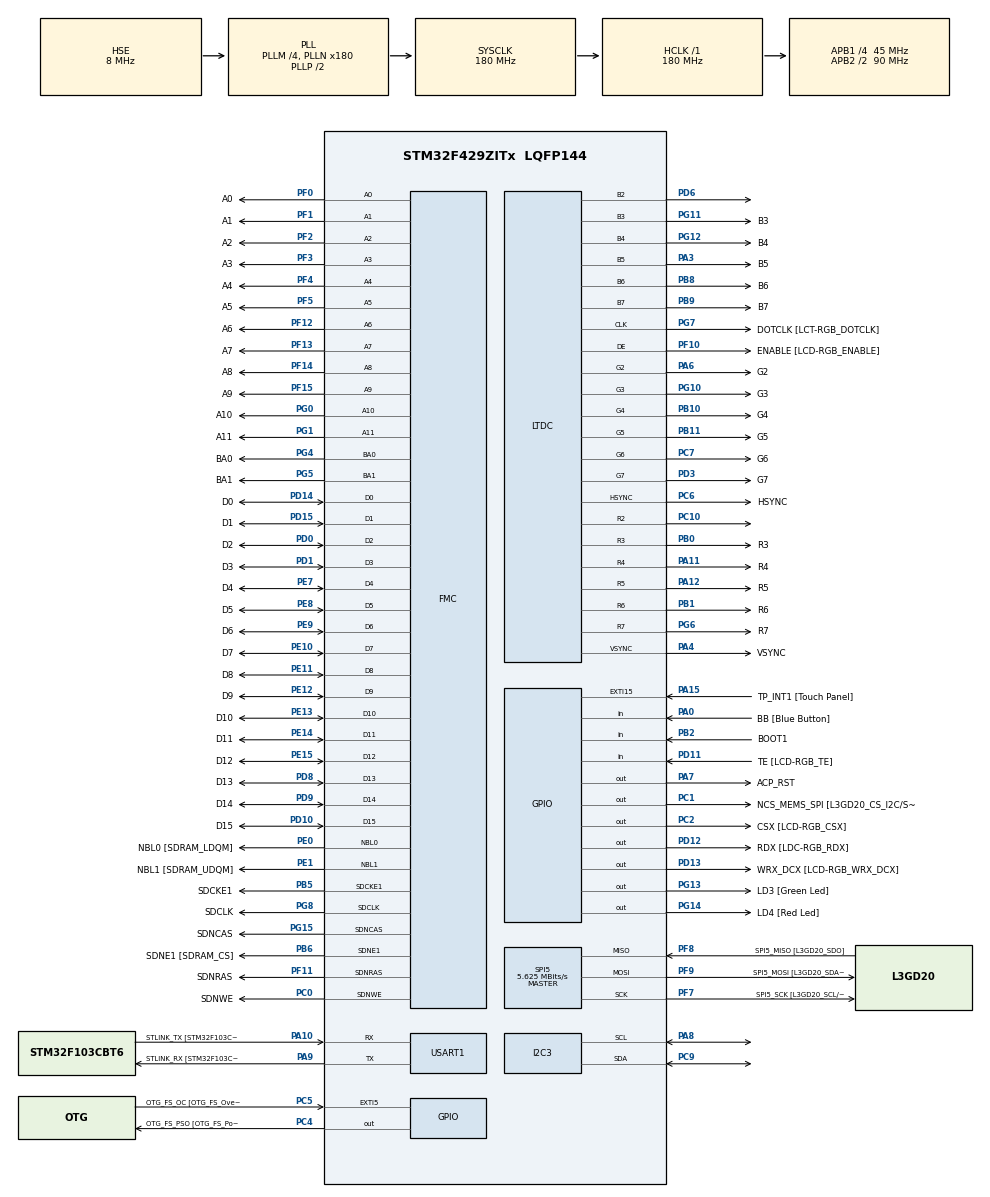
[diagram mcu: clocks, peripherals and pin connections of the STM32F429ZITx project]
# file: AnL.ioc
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DMA2D.ColorMode=DMA2D_OUTPUT_RGB565
FMC.CASLatency1=FMC_SDRAM_CAS_LATENCY_3
FMC.ExitSelfRefreshDelay1=7
FMC.LoadToActiveDelay1=2
FMC.RCDDelay1=2
FMC.RPDelay1=2
FMC.RPDelay2=2
FMC.ReadBurst1=FMC_SDRAM_RBURST_DISABLE
FMC.ReadPipeDelay1=FMC_SDRAM_RPIPE_DELAY_1
FMC.ReadPipeDelay2=FMC_SDRAM_RPIPE_DELAY_1
FMC.RowCycleDelay1=7
FMC.RowCycleDelay2=7
FMC.SDClockPeriod1=FMC_SDRAM_CLOCK_PERIOD_2
FMC.SDClockPeriod2=FMC_SDRAM_CLOCK_PERIOD_2
FMC.SelfRefreshTime1=4
FMC.WriteRecoveryTime1=3
LTDC.ActiveH=320
LTDC.ActiveW=240
LTDC.Alpha_L0=255
LTDC.BlendingFactor1_L0=LTDC_BLENDING_FACTOR1_PAxCA
LTDC.BlendingFactor2_L0=LTDC_BLENDING_FACTOR2_PAxCA
LTDC.FBStartAdress_L0=0xD0000000
LTDC.HBP=20
LTDC.HFP=10
LTDC.HSync=10
LTDC.ImageHeight_L0=320
LTDC.ImageWidth_L0=240
LTDC.Layers=0
LTDC.PixelFormat_L0=LTDC_PIXEL_FORMAT_RGB565
LTDC.VFP=4
LTDC.VSync=2
LTDC.WindowX1_L0=240
LTDC.WindowY1_L0=320
Mcu.Family=STM32F4
Mcu.Name=STM32F429ZITx
Mcu.Package=LQFP144
NVIC.DMA2D_IRQn=true\:5\:0\:true\:false\:true\:true\:true
NVIC.LTDC_IRQn=true\:5\:0\:true\:false\:true\:true\:true
NVIC.PriorityGroup=NVIC_PRIORITYGROUP_4
NVIC.TIM1_TRG_COM_TIM11_IRQn=true\:0\:0\:false\:false\:true\:true\:true
NVIC.TIM1_UP_TIM10_IRQn=true\:0\:0\:false\:false\:true\:true\:true
NVIC.TIM6_DAC_IRQn=true\:0\:0\:false\:false\:true\:false\:true
NVIC.TimeBase=TIM6_DAC_IRQn
NVIC.TimeBaseIP=TIM6
PA0/WKUP.GPIO_Label=BB [Blue Button]
PA0/WKUP.Signal=GPIO_Input
PA10.GPIO_Label=STLINK_TX [STM32F103CBT6_PA2]
PA10.Mode=Asynchronous
PA10.Signal=USART1_RX
PA11.GPIO_Label=R4
PA11.GPIO_Mode=GPIO_MODE_AF_PP
PA11.GPIO_PuPd=GPIO_NOPULL
PA11.GPIO_Speed=GPIO_SPEED_FREQ_LOW
PA11.Mode=RGB666
PA11.Signal=LTDC_R4
PA12.GPIO_Label=R5
PA12.GPIO_Mode=GPIO_MODE_AF_PP
PA12.GPIO_PuPd=GPIO_NOPULL
PA12.GPIO_Speed=GPIO_SPEED_FREQ_LOW
PA12.Mode=RGB666
PA12.Signal=LTDC_R5
PA13.GPIO_Label=SWDIO
PA13.Mode=Serial_Wire
PA13.Signal=SYS_JTMS-SWDIO
PA14.GPIO_Label=SWCLK
PA14.Mode=Serial_Wire
PA14.Signal=SYS_JTCK-SWCLK
PA15.GPIO_Label=TP_INT1 [Touch Panel]
PA15.GPIO_ModeDefaultEXTI=GPIO_MODE_EVT_RISING
PA15.GPIO_PuPd=GPIO_NOPULL
PA15.Signal=GPXTI15
PA3.GPIO_Label=B5
PA3.GPIO_Mode=GPIO_MODE_AF_PP
PA3.GPIO_PuPd=GPIO_NOPULL
PA3.GPIO_Speed=GPIO_SPEED_FREQ_LOW
PA3.Mode=RGB666
PA3.Signal=LTDC_B5
PA4.GPIO_Label=VSYNC
PA4.GPIO_Mode=GPIO_MODE_AF_PP
PA4.GPIO_PuPd=GPIO_NOPULL
PA4.GPIO_Speed=GPIO_SPEED_FREQ_LOW
PA4.Mode=RGB666
PA4.Signal=LTDC_VSYNC
PA6.GPIO_Label=G2
PA6.GPIO_Mode=GPIO_MODE_AF_PP
PA6.GPIO_PuPd=GPIO_NOPULL
PA6.GPIO_Speed=GPIO_SPEED_FREQ_LOW
PA6.Mode=RGB666
PA6.Signal=LTDC_G2
PA7.GPIO_Label=ACP_RST
PA7.GPIO_Mode=GPIO_MODE_OUTPUT_PP
PA7.GPIO_PuPd=GPIO_NOPULL
PA7.GPIO_Speed=GPIO_SPEED_FREQ_LOW
PA7.Signal=GPIO_Output
PA8.Mode=I2C
PA8.Signal=I2C3_SCL
PA9.GPIO_Label=STLINK_RX [STM32F103CBT6_PA3]
PA9.Mode=Asynchronous
PA9.Signal=USART1_TX
PB0.GPIO_Label=R3
PB0.GPIO_Mode=GPIO_MODE_AF_PP
PB0.GPIO_PuPd=GPIO_NOPULL
PB0.GPIO_Speed=GPIO_SPEED_FREQ_LOW
PB0.Mode=RGB666
PB0.Signal=LTDC_R3
PB1.GPIO_Label=R6
PB1.GPIO_Mode=GPIO_MODE_AF_PP
PB1.GPIO_PuPd=GPIO_NOPULL
PB1.GPIO_Speed=GPIO_SPEED_FREQ_LOW
PB1.Mode=RGB666
PB1.Signal=LTDC_R6
PB10.GPIO_Label=G4
PB10.GPIO_Mode=GPIO_MODE_AF_PP
PB10.GPIO_PuPd=GPIO_NOPULL
PB10.GPIO_Speed=GPIO_SPEED_FREQ_LOW
PB10.Mode=RGB666
PB10.Signal=LTDC_G4
PB11.GPIO_Label=G5
PB11.GPIO_Mode=GPIO_MODE_AF_PP
PB11.GPIO_PuPd=GPIO_NOPULL
PB11.GPIO_Speed=GPIO_SPEED_FREQ_LOW
PB11.Mode=RGB666
PB11.Signal=LTDC_G5
PB2/BOOT1.GPIO_Label=BOOT1
PB2/BOOT1.GPIO_Mode=GPIO_MODE_INPUT
PB2/BOOT1.GPIO_PuPd=GPIO_NOPULL
PB2/BOOT1.Signal=GPIO_Input
PB5.GPIO_Label=SDCKE1
PB5.GPIO_Mode=GPIO_MODE_AF_PP
PB5.GPIO_PuPd=GPIO_NOPULL
PB5.GPIO_Speed=GPIO_SPEED_FREQ_VERY_HIGH
PB5.Mode=SdramChipSelect2_1
PB5.Signal=FMC_SDCKE1
PB6.GPIO_Label=SDNE1 [SDRAM_CS]
PB6.GPIO_Mode=GPIO_MODE_AF_PP
PB6.GPIO_PuPd=GPIO_NOPULL
PB6.GPIO_Speed=GPIO_SPEED_FREQ_VERY_HIGH
PB6.Mode=SdramChipSelect2_1
PB6.Signal=FMC_SDNE1
PB8.GPIO_Label=B6
PB8.GPIO_Mode=GPIO_MODE_AF_PP
PB8.GPIO_PuPd=GPIO_NOPULL
PB8.GPIO_Speed=GPIO_SPEED_FREQ_LOW
PB8.Mode=RGB666
PB8.Signal=LTDC_B6
PB9.GPIO_Label=B7
PB9.GPIO_Mode=GPIO_MODE_AF_PP
PB9.GPIO_PuPd=GPIO_NOPULL
PB9.GPIO_Speed=GPIO_SPEED_FREQ_LOW
PB9.Mode=RGB666
PB9.Signal=LTDC_B7
PC0.GPIO_Label=SDNWE
PC0.GPIO_Mode=GPIO_MODE_AF_PP
PC0.GPIO_PuPd=GPIO_NOPULL
PC0.GPIO_Speed=GPIO_SPEED_FREQ_VERY_HIGH
PC0.Signal=FMC_SDNWE
PC1.GPIO_Label=NCS_MEMS_SPI [L3GD20_CS_I2C/SPI]
PC1.GPIO_Mode=GPIO_MODE_OUTPUT_PP
PC1.GPIO_PuPd=GPIO_NOPULL
PC1.GPIO_Speed=GPIO_SPEED_FREQ_LOW
PC1.Signal=GPIO_Output
PC10.Mode=RGB666
PC10.Signal=LTDC_R2
PC2.GPIO_Label=CSX [LCD-RGB_CSX]
PC2.GPIO_Mode=GPIO_MODE_OUTPUT_PP
PC2.GPIO_PuPd=GPIO_NOPULL
PC2.GPIO_Speed=GPIO_SPEED_FREQ_LOW
PC2.Signal=GPIO_Output
PC4.GPIO_Label=OTG_FS_PSO [OTG_FS_PowerSwitchOn]
PC4.GPIO_Mode=GPIO_MODE_OUTPUT_PP
PC4.GPIO_PuPd=GPIO_NOPULL
PC4.GPIO_Speed=GPIO_SPEED_FREQ_LOW
PC4.Signal=GPIO_Output
PC5.GPIO_Label=OTG_FS_OC [OTG_FS_OverCurrent]
PC5.GPIO_ModeDefaultEXTI=GPIO_MODE_EVT_RISING
PC5.Signal=GPXTI5
PC6.GPIO_Label=HSYNC
PC6.GPIO_Mode=GPIO_MODE_AF_PP
PC6.GPIO_PuPd=GPIO_NOPULL
PC6.GPIO_Speed=GPIO_SPEED_FREQ_LOW
PC6.Mode=RGB666
PC6.Signal=LTDC_HSYNC
PC7.GPIO_Label=G6
PC7.GPIO_Mode=GPIO_MODE_AF_PP
PC7.GPIO_PuPd=GPIO_NOPULL
PC7.GPIO_Speed=GPIO_SPEED_FREQ_LOW
PC7.Mode=RGB666
PC7.Signal=LTDC_G6
PC9.Mode=I2C
PC9.Signal=I2C3_SDA
PD0.GPIO_Label=D2
PD0.GPIO_Mode=GPIO_MODE_AF_PP
PD0.GPIO_PuPd=GPIO_NOPULL
PD0.GPIO_Speed=GPIO_SPEED_FREQ_VERY_HIGH
PD0.Signal=FMC_D2_DA2
PD1.GPIO_Label=D3
PD1.GPIO_Mode=GPIO_MODE_AF_PP
PD1.GPIO_PuPd=GPIO_NOPULL
PD1.GPIO_Speed=GPIO_SPEED_FREQ_VERY_HIGH
PD1.Signal=FMC_D3_DA3
PD10.GPIO_Label=D15
PD10.GPIO_Mode=GPIO_MODE_AF_PP
PD10.GPIO_PuPd=GPIO_NOPULL
PD10.GPIO_Speed=GPIO_SPEED_FREQ_VERY_HIGH
PD10.Signal=FMC_D15_DA15
PD11.GPIO_Label=TE [LCD-RGB_TE]
PD11.GPIO_Mode=GPIO_MODE_INPUT
PD11.GPIO_PuPd=GPIO_NOPULL
PD11.Signal=GPIO_Input
PD12.GPIO_Label=RDX [LDC-RGB_RDX]
PD12.GPIO_Mode=GPIO_MODE_OUTPUT_PP
PD12.GPIO_PuPd=GPIO_NOPULL
PD12.GPIO_Speed=GPIO_SPEED_FREQ_LOW
PD12.Signal=GPIO_Output
PD13.GPIO_Label=WRX_DCX [LCD-RGB_WRX_DCX]
PD13.GPIO_Mode=GPIO_MODE_OUTPUT_PP
PD13.GPIO_PuPd=GPIO_NOPULL
PD13.GPIO_Speed=GPIO_SPEED_FREQ_LOW
PD13.Signal=GPIO_Output
PD14.GPIO_Label=D0
PD14.GPIO_Mode=GPIO_MODE_AF_PP
PD14.GPIO_PuPd=GPIO_NOPULL
PD14.GPIO_Speed=GPIO_SPEED_FREQ_VERY_HIGH
PD14.Signal=FMC_D0_DA0
PD15.GPIO_Label=D1
PD15.GPIO_Mode=GPIO_MODE_AF_PP
PD15.GPIO_PuPd=GPIO_NOPULL
PD15.GPIO_Speed=GPIO_SPEED_FREQ_VERY_HIGH
PD15.Signal=FMC_D1_DA1
PD3.GPIO_Label=G7
PD3.GPIO_Mode=GPIO_MODE_AF_PP
PD3.GPIO_PuPd=GPIO_NOPULL
PD3.GPIO_Speed=GPIO_SPEED_FREQ_LOW
PD3.Mode=RGB666
PD3.Signal=LTDC_G7
PD6.Mode=RGB666
PD6.Signal=LTDC_B2
PD8.GPIO_Label=D13
PD8.GPIO_Mode=GPIO_MODE_AF_PP
PD8.GPIO_PuPd=GPIO_NOPULL
PD8.GPIO_Speed=GPIO_SPEED_FREQ_VERY_HIGH
PD8.Signal=FMC_D13_DA13
PD9.GPIO_Label=D14
PD9.GPIO_Mode=GPIO_MODE_AF_PP
PD9.GPIO_PuPd=GPIO_NOPULL
PD9.GPIO_Speed=GPIO_SPEED_FREQ_VERY_HIGH
PD9.Signal=FMC_D14_DA14
PE0.GPIO_Label=NBL0 [SDRAM_LDQM]
PE0.GPIO_Mode=GPIO_MODE_AF_PP
PE0.GPIO_PuPd=GPIO_NOPULL
PE0.GPIO_Speed=GPIO_SPEED_FREQ_VERY_HIGH
PE0.Signal=FMC_NBL0
PE1.GPIO_Label=NBL1 [SDRAM_UDQM]
PE1.GPIO_Mode=GPIO_MODE_AF_PP
PE1.GPIO_PuPd=GPIO_NOPULL
PE1.GPIO_Speed=GPIO_SPEED_FREQ_VERY_HIGH
PE1.Signal=FMC_NBL1
PE10.GPIO_Label=D7
PE10.GPIO_Mode=GPIO_MODE_AF_PP
PE10.GPIO_PuPd=GPIO_NOPULL
PE10.GPIO_Speed=GPIO_SPEED_FREQ_VERY_HIGH
PE10.Signal=FMC_D7_DA7
PE11.GPIO_Label=D8
PE11.GPIO_Mode=GPIO_MODE_AF_PP
PE11.GPIO_PuPd=GPIO_NOPULL
PE11.GPIO_Speed=GPIO_SPEED_FREQ_VERY_HIGH
PE11.Signal=FMC_D8_DA8
PE12.GPIO_Label=D9
PE12.GPIO_Mode=GPIO_MODE_AF_PP
PE12.GPIO_PuPd=GPIO_NOPULL
PE12.GPIO_Speed=GPIO_SPEED_FREQ_VERY_HIGH
PE12.Signal=FMC_D9_DA9
PE13.GPIO_Label=D10
PE13.GPIO_Mode=GPIO_MODE_AF_PP
PE13.GPIO_PuPd=GPIO_NOPULL
PE13.GPIO_Speed=GPIO_SPEED_FREQ_VERY_HIGH
PE13.Signal=FMC_D10_DA10
PE14.GPIO_Label=D11
PE14.GPIO_Mode=GPIO_MODE_AF_PP
PE14.GPIO_PuPd=GPIO_NOPULL
PE14.GPIO_Speed=GPIO_SPEED_FREQ_VERY_HIGH
PE14.Signal=FMC_D11_DA11
PE15.GPIO_Label=D12
PE15.GPIO_Mode=GPIO_MODE_AF_PP
PE15.GPIO_PuPd=GPIO_NOPULL
PE15.GPIO_Speed=GPIO_SPEED_FREQ_VERY_HIGH
PE15.Signal=FMC_D12_DA12
PE7.GPIO_Label=D4
PE7.GPIO_Mode=GPIO_MODE_AF_PP
PE7.GPIO_PuPd=GPIO_NOPULL
PE7.GPIO_Speed=GPIO_SPEED_FREQ_VERY_HIGH
PE7.Signal=FMC_D4_DA4
PE8.GPIO_Label=D5
PE8.GPIO_Mode=GPIO_MODE_AF_PP
PE8.GPIO_PuPd=GPIO_NOPULL
PE8.GPIO_Speed=GPIO_SPEED_FREQ_VERY_HIGH
PE8.Signal=FMC_D5_DA5
PE9.GPIO_Label=D6
PE9.GPIO_Mode=GPIO_MODE_AF_PP
PE9.GPIO_PuPd=GPIO_NOPULL
PE9.GPIO_Speed=GPIO_SPEED_FREQ_VERY_HIGH
PE9.Signal=FMC_D6_DA6
PF0.GPIO_Label=A0
PF0.GPIO_Mode=GPIO_MODE_AF_PP
PF0.GPIO_PuPd=GPIO_NOPULL
PF0.GPIO_Speed=GPIO_SPEED_FREQ_VERY_HIGH
PF0.Signal=FMC_A0
PF1.GPIO_Label=A1
PF1.GPIO_Mode=GPIO_MODE_AF_PP
PF1.GPIO_PuPd=GPIO_NOPULL
PF1.GPIO_Speed=GPIO_SPEED_FREQ_VERY_HIGH
PF1.Signal=FMC_A1
PF10.GPIO_Label=ENABLE [LCD-RGB_ENABLE]
PF10.GPIO_Mode=GPIO_MODE_AF_PP
PF10.GPIO_PuPd=GPIO_NOPULL
PF10.GPIO_Speed=GPIO_SPEED_FREQ_LOW
PF10.Mode=RGB666
PF10.Signal=LTDC_DE
PF11.GPIO_Label=SDNRAS
PF11.GPIO_Mode=GPIO_MODE_AF_PP
PF11.GPIO_PuPd=GPIO_NOPULL
PF11.GPIO_Speed=GPIO_SPEED_FREQ_VERY_HIGH
PF11.Signal=FMC_SDNRAS
PF12.GPIO_Label=A6
PF12.GPIO_Mode=GPIO_MODE_AF_PP
PF12.GPIO_PuPd=GPIO_NOPULL
PF12.GPIO_Speed=GPIO_SPEED_FREQ_VERY_HIGH
PF12.Signal=FMC_A6
PF13.GPIO_Label=A7
PF13.GPIO_Mode=GPIO_MODE_AF_PP
PF13.GPIO_PuPd=GPIO_NOPULL
PF13.GPIO_Speed=GPIO_SPEED_FREQ_VERY_HIGH
PF13.Signal=FMC_A7
PF14.GPIO_Label=A8
PF14.GPIO_Mode=GPIO_MODE_AF_PP
PF14.GPIO_PuPd=GPIO_NOPULL
PF14.GPIO_Speed=GPIO_SPEED_FREQ_VERY_HIGH
PF14.Signal=FMC_A8
PF15.GPIO_Label=A9
PF15.GPIO_Mode=GPIO_MODE_AF_PP
PF15.GPIO_PuPd=GPIO_NOPULL
PF15.GPIO_Speed=GPIO_SPEED_FREQ_VERY_HIGH
PF15.Signal=FMC_A9
PF2.GPIO_Label=A2
PF2.GPIO_Mode=GPIO_MODE_AF_PP
PF2.GPIO_PuPd=GPIO_NOPULL
PF2.GPIO_Speed=GPIO_SPEED_FREQ_VERY_HIGH
PF2.Signal=FMC_A2
PF3.GPIO_Label=A3
PF3.GPIO_Mode=GPIO_MODE_AF_PP
PF3.GPIO_PuPd=GPIO_NOPULL
PF3.GPIO_Speed=GPIO_SPEED_FREQ_VERY_HIGH
PF3.Signal=FMC_A3
PF4.GPIO_Label=A4
PF4.GPIO_Mode=GPIO_MODE_AF_PP
PF4.GPIO_PuPd=GPIO_NOPULL
PF4.GPIO_Speed=GPIO_SPEED_FREQ_VERY_HIGH
PF4.Signal=FMC_A4
PF5.GPIO_Label=A5
PF5.GPIO_Mode=GPIO_MODE_AF_PP
PF5.GPIO_PuPd=GPIO_NOPULL
PF5.GPIO_Speed=GPIO_SPEED_FREQ_VERY_HIGH
PF5.Signal=FMC_A5
PF7.GPIO_Label=SPI5_SCK [L3GD20_SCL/SPC]
PF7.GPIO_Mode=GPIO_MODE_AF_PP
PF7.GPIO_PuPd=GPIO_NOPULL
PF7.GPIO_Speed=GPIO_SPEED_FREQ_LOW
PF7.Mode=Full_Duplex_Master
PF7.Signal=SPI5_SCK
PF8.GPIO_Label=SPI5_MISO [L3GD20_SDO]
PF8.GPIO_Mode=GPIO_MODE_AF_PP
PF8.GPIO_PuPd=GPIO_NOPULL
PF8.GPIO_Speed=GPIO_SPEED_FREQ_LOW
PF8.Mode=Full_Duplex_Master
PF8.Signal=SPI5_MISO
PF9.GPIO_Label=SPI5_MOSI [L3GD20_SDA/SDI/SDO]
PF9.GPIO_Mode=GPIO_MODE_AF_PP
PF9.GPIO_PuPd=GPIO_NOPULL
PF9.GPIO_Speed=GPIO_SPEED_FREQ_LOW
PF9.Mode=Full_Duplex_Master
PF9.Signal=SPI5_MOSI
PG0.GPIO_Label=A10
PG0.GPIO_Mode=GPIO_MODE_AF_PP
PG0.GPIO_PuPd=GPIO_NOPULL
PG0.GPIO_Speed=GPIO_SPEED_FREQ_VERY_HIGH
PG0.Signal=FMC_A10
PG1.GPIO_Label=A11
PG1.GPIO_Mode=GPIO_MODE_AF_PP
PG1.GPIO_PuPd=GPIO_NOPULL
PG1.GPIO_Speed=GPIO_SPEED_FREQ_VERY_HIGH
PG1.Signal=FMC_A11
PG10.GPIO_Label=G3
PG10.GPIO_Mode=GPIO_MODE_AF_PP
PG10.GPIO_PuPd=GPIO_NOPULL
PG10.GPIO_Speed=GPIO_SPEED_FREQ_LOW
PG10.Mode=RGB666
PG10.Signal=LTDC_G3
PG11.GPIO_Label=B3
PG11.GPIO_Mode=GPIO_MODE_AF_PP
PG11.GPIO_PuPd=GPIO_NOPULL
PG11.GPIO_Speed=GPIO_SPEED_FREQ_LOW
PG11.Mode=RGB666
PG11.Signal=LTDC_B3
PG12.GPIO_Label=B4
PG12.GPIO_Mode=GPIO_MODE_AF_PP
PG12.GPIO_PuPd=GPIO_NOPULL
PG12.GPIO_Speed=GPIO_SPEED_FREQ_LOW
PG12.Mode=RGB666
PG12.Signal=LTDC_B4
PG13.GPIO_Label=LD3 [Green Led]
PG13.GPIO_Mode=GPIO_MODE_OUTPUT_PP
PG13.GPIO_PuPd=GPIO_NOPULL
PG13.GPIO_Speed=GPIO_SPEED_FREQ_LOW
PG13.Signal=GPIO_Output
PG14.GPIO_Label=LD4 [Red Led]
PG14.GPIO_Mode=GPIO_MODE_OUTPUT_PP
PG14.GPIO_PuPd=GPIO_NOPULL
PG14.GPIO_Speed=GPIO_SPEED_FREQ_LOW
PG14.Signal=GPIO_Output
PG15.GPIO_Label=SDNCAS
PG15.GPIO_Mode=GPIO_MODE_AF_PP
PG15.GPIO_PuPd=GPIO_NOPULL
PG15.GPIO_Speed=GPIO_SPEED_FREQ_VERY_HIGH
PG15.Signal=FMC_SDNCAS
PG4.GPIO_Label=BA0
PG4.GPIO_Mode=GPIO_MODE_AF_PP
PG4.GPIO_PuPd=GPIO_NOPULL
PG4.GPIO_Speed=GPIO_SPEED_FREQ_VERY_HIGH
PG4.Signal=FMC_A14_BA0
PG5.GPIO_Label=BA1
PG5.GPIO_Mode=GPIO_MODE_AF_PP
PG5.GPIO_PuPd=GPIO_NOPULL
PG5.GPIO_Speed=GPIO_SPEED_FREQ_VERY_HIGH
PG5.Signal=FMC_A15_BA1
PG6.GPIO_Label=R7
PG6.GPIO_Mode=GPIO_MODE_AF_PP
PG6.GPIO_PuPd=GPIO_NOPULL
PG6.GPIO_Speed=GPIO_SPEED_FREQ_LOW
PG6.Mode=RGB666
PG6.Signal=LTDC_R7
PG7.GPIO_Label=DOTCLK [LCT-RGB_DOTCLK]
PG7.GPIO_Mode=GPIO_MODE_AF_PP
PG7.GPIO_PuPd=GPIO_NOPULL
PG7.GPIO_Speed=GPIO_SPEED_FREQ_LOW
PG7.Mode=RGB666
PG7.Signal=LTDC_CLK
PG8.GPIO_Label=SDCLK
PG8.GPIO_Mode=GPIO_MODE_AF_PP
PG8.GPIO_PuPd=GPIO_NOPULL
PG8.GPIO_Speed=GPIO_SPEED_FREQ_VERY_HIGH
PG8.Signal=FMC_SDCLK
PH0/OSC_IN.GPIO_Label=PH0-OSC_IN
PH0/OSC_IN.Mode=HSE-External-Oscillator
PH0/OSC_IN.Signal=RCC_OSC_IN
PH1/OSC_OUT.GPIO_Label=PH1-OSC_OUT
PH1/OSC_OUT.Mode=HSE-External-Oscillator
PH1/OSC_OUT.Signal=RCC_OSC_OUT
ProjectManager.HeapSize=0x200
ProjectManager.StackSize=0x400
ProjectManager.TargetToolchain=TrueSTUDIO
RCC.48MHZClocksFreq_Value=120000000
RCC.AHBFreq_Value=180000000
RCC.APB1CLKDivider=RCC_HCLK_DIV4
RCC.APB1Freq_Value=45000000
RCC.APB1TimFreq_Value=90000000
RCC.APB2CLKDivider=RCC_HCLK_DIV2
RCC.APB2Freq_Value=90000000
RCC.APB2TimFreq_Value=180000000
RCC.CortexFreq_Value=180000000
RCC.HCLKFreq_Value=180000000
RCC.HSE_VALUE=8000000
RCC.HSI_VALUE=16000000
RCC.LSE_VALUE=32768
RCC.PLLM=4
RCC.PLLN=180
RCC.PLLQ=3
RCC.PLLSAIN=192
RCC.PLLSourceVirtual=RCC_PLLSOURCE_HSE
RCC.SYSCLKFreq_VALUE=180000000
RCC.SYSCLKSource=RCC_SYSCLKSOURCE_PLLCLK
RCC.VCOOutputFreq_Value=360000000
SH.FMC_A0.0=FMC_A0,12b-sda1
SH.FMC_A1.0=FMC_A1,12b-sda1
SH.FMC_A10.0=FMC_A10,12b-sda1
SH.FMC_A11.0=FMC_A11,12b-sda1
SH.FMC_A14_BA0.0=FMC_BA0,FourSdramBanks1
SH.FMC_A15_BA1.0=FMC_BA1,FourSdramBanks1
SH.FMC_A2.0=FMC_A2,12b-sda1
SH.FMC_A3.0=FMC_A3,12b-sda1
SH.FMC_A4.0=FMC_A4,12b-sda1
SH.FMC_A5.0=FMC_A5,12b-sda1
SH.FMC_A6.0=FMC_A6,12b-sda1
SH.FMC_A7.0=FMC_A7,12b-sda1
SH.FMC_A8.0=FMC_A8,12b-sda1
SH.FMC_A9.0=FMC_A9,12b-sda1
SH.FMC_D0_DA0.0=FMC_D0,sd-16b-d1
SH.FMC_D10_DA10.0=FMC_D10,sd-16b-d1
SH.FMC_D11_DA11.0=FMC_D11,sd-16b-d1
SH.FMC_D12_DA12.0=FMC_D12,sd-16b-d1
SH.FMC_D13_DA13.0=FMC_D13,sd-16b-d1
SH.FMC_D14_DA14.0=FMC_D14,sd-16b-d1
SH.FMC_D15_DA15.0=FMC_D15,sd-16b-d1
SH.FMC_D1_DA1.0=FMC_D1,sd-16b-d1
SH.FMC_D2_DA2.0=FMC_D2,sd-16b-d1
SH.FMC_D3_DA3.0=FMC_D3,sd-16b-d1
SH.FMC_D4_DA4.0=FMC_D4,sd-16b-d1
SH.FMC_D5_DA5.0=FMC_D5,sd-16b-d1
SH.FMC_D6_DA6.0=FMC_D6,sd-16b-d1
SH.FMC_D7_DA7.0=FMC_D7,sd-16b-d1
SH.FMC_D8_DA8.0=FMC_D8,sd-16b-d1
SH.FMC_D9_DA9.0=FMC_D9,sd-16b-d1
SH.FMC_NBL0.0=FMC_NBL0,Sd2ByteEnable1
SH.FMC_NBL1.0=FMC_NBL1,Sd2ByteEnable1
SH.FMC_SDCLK.0=FMC_SDCLK,12b-sda1
SH.FMC_SDNCAS.0=FMC_SDNCAS,12b-sda1
SH.FMC_SDNRAS.0=FMC_SDNRAS,12b-sda1
SH.FMC_SDNWE.0=FMC_SDNWE,12b-sda1
SPI5.BaudRatePrescaler=SPI_BAUDRATEPRESCALER_16
SPI5.CalculateBaudRate=5.625 MBits/s
SPI5.Direction=SPI_DIRECTION_2LINES
SPI5.Mode=SPI_MODE_MASTER
SPI5.VirtualType=VM_MASTER
TIM10.Period=288
TIM10.Prescaler=9999
TIM11.Period=71
TIM11.Prescaler=9999
USART1.VirtualMode=VM_ASYNC
VP_CRC_VS_CRC.Mode=CRC_Activate
VP_DMA2D_VS_DMA2D.Mode=DMA2D_Activate
VP_SYS_VS_tim6.Mode=TIM6
VP_TIM10_VS_ClockSourceINT.Mode=Enable_Timer
VP_TIM11_VS_ClockSourceINT.Mode=Enable_Timer
VP_TIM1_VS_ClockSourceINT.Mode=Internal
board=32F429IDISCOVERY

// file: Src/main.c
/* USER CODE BEGIN Header */
/**
 ******************************************************************************
 * @file           : main.c
 * @brief          : Main program body
 ******************************************************************************
 * @attention
 *
 * <h2><center>&copy; Copyright (c) 2019 STMicroelectronics.
 * All rights reserved.</center></h2>
 *
 * This software component is licensed by ST under Ultimate Liberty license
 * SLA0044, the "License"; You may not use this file except in compliance with
 * the License. You may obtain a copy of the License at:
 *                             www.st.com/SLA0044
 *
 ******************************************************************************
 */
/* USER CODE END Header */

#include "main.h"
#include "crc.h"
#include "dma2d.h"
#include "gfxsimulator.h"
#include "i2c.h"
#include "ltdc.h"
#include "spi.h"
#include "tim.h"
#include "usart.h"
#include "gpio.h"
#include "fmc.h"

/* USER CODE BEGIN Includes */
#include "../Drivers/BSP/STM32F429I-Discovery/stm32f429i_discovery_lcd.h"
#include "../Drivers/BSP/STM32F429I-Discovery/stm32f429i_discovery_gyroscope.h"
#include "../Drivers/BSP/STM32F429I-Discovery/Fonts/fonts.h"
//#include "Menu.h"
#include "Menu_kontynuuj.h"
#include "Menu_nowagra.h"
#include "Menu_poziomy.h"
//#include "mapa1.h"
#include "mapa2.h"
//#include "SciezkaMapy1.h"
#include "PunktySciezki.h"

/* USER CODE END Includes */

/* USER CODE BEGIN PD */
#define SPOWOLNIENIE_KULKI 5

/* USER CODE END PD */

/* USER CODE BEGIN PV */
volatile ZyroskopDane DataOld, DataNow;
volatile int32_t AngleX, AngleY, AngleZ;

//Dane dla czesci testowej*****************
volatile ZyroskopDane DataTempRom[4];
volatile ZyroskopDane DataTempRich;

volatile int32_t CalkaTrapX, CalkaTrapY;
volatile int32_t CalkaRichaX, CalkaRichaY;
volatile int32_t CalkaRombX, CalkaRombY;
volatile int32_t CalkaPosrednia1X, CalkaPosrednia1Y;
volatile int32_t CalkaPosrednia2X, CalkaPosrednia2Y;
volatile int32_t CalkaPosredniaRomX[4];
volatile int32_t CalkaPosredniaRomY[4];
volatile int32_t CalkaPomocniczaRomX[3];
volatile int32_t CalkaPomocniczaRomY[3];
volatile int32_t CalkaPomocnicza2RomX[2];
volatile int32_t CalkaPomocnicza2RomY[2];

volatile uint8_t LicznikPomocniczy;
volatile uint8_t LicznikPomocniczyRomberg;

volatile int32_t X_pri;
volatile int32_t X_post;
volatile int32_t V_priX;
volatile int32_t V_postX;

volatile int32_t Y_pri;
volatile int32_t Y_post;
volatile int32_t V_priY;
volatile int32_t V_postY;
//*****************************************

//Zmienne stanu gry************************
volatile eStanGry StanGry;
volatile eStanMenu StanMenu;
volatile uint8_t ZmienionoStanMenu;
volatile uint8_t ZmienionoStanPoziomow;
volatile uint8_t WybranyPoziom;
volatile uint32_t czasZmiany;
volatile uint8_t RozpoczetoNowaGre;
volatile uint8_t CzyGra;
volatile uint8_t KontynuowanaGra;
volatile uint8_t Wygrana;
//*****************************************

//Zmiana stanu przycisku*******************
GPIO_PinState StanPrzycisku;
GPIO_PinState PoprzedniStanPrzycisku = GPIO_PIN_RESET;
uint32_t PoprzedniCzasPrzycisku;
//*****************************************

//Zmiana rozgrywki*************************
volatile uint32_t PozycjaNaSciezce;
volatile uint8_t OpoznienieDodatniX;
volatile uint8_t OpoznienieDodatniY;
volatile uint8_t OpoznienieUjemnyX;
volatile uint8_t OpoznienieUjemnyY;
//*****************************************

float dT;
uint8_t Animacja;
volatile uint16_t X, Y;
volatile uint16_t PoprzednieX, PoprzednieY;
volatile uint8_t Direction;
volatile uint8_t fMovedX;
volatile uint8_t fMovedY;
volatile uint16_t ResetTimeX;
volatile uint16_t ResetTimeY;

DMA2D_HandleTypeDef hdma2d;
I2C_HandleTypeDef hi2c3;
LTDC_HandleTypeDef hltdc;
SPI_HandleTypeDef hspi5;
SDRAM_HandleTypeDef hsdram1;
/* USER CODE END PV */

void SystemClock_Config(void);

/* USER CODE BEGIN 0 */
uint8_t spi5_sendrecv(uint8_t byte) {
	uint8_t answer;

	HAL_SPI_TransmitReceive(&hspi5, &byte, &answer, 1, HAL_MAX_DELAY);

	return answer;
}

uint8_t SPI5_read(uint8_t address) {
	uint8_t dane;
	HAL_GPIO_WritePin(GPIOC, GPIO_PIN_1, GPIO_PIN_RESET);
	spi5_sendrecv(address | 0x80);
	dane = spi5_sendrecv(0xFF);
	HAL_GPIO_WritePin(GPIOC, GPIO_PIN_1, GPIO_PIN_SET);

	return dane;
}

void SPI5_write(uint8_t address, uint8_t data) {
	HAL_GPIO_WritePin(GPIOC, GPIO_PIN_1, GPIO_PIN_RESET);
	spi5_sendrecv(address);
	data = spi5_sendrecv(data);
	HAL_GPIO_WritePin(GPIOC, GPIO_PIN_1, GPIO_PIN_SET);

}

uint8_t OurL3GD20_Init() {
	if (SPI5_read(0x0F) != 0b11010100) {

		return 1;
	}

	//Enable L3GD20 Power bit
	SPI5_write(0x20, 0xFF);

	//Set L3GD20 scale

	SPI5_write(0x23, 0x00);

	//Set high-pass filter settings
	SPI5_write(0x21, 0x00);

	//Enable high-pass filter
	SPI5_write(0x24, 0x10);

	//Everything OK
	return 0;
}

void OurL3GD20_Read() {
	float s;
	short temp1, temp2, temp3;

	// Read X axis

	temp1 = (SPI5_read(0x28) | SPI5_read(0x29) << 8);
	temp2 = (SPI5_read(0x2A) | SPI5_read(0x2B) << 8);
	temp3 = (SPI5_read(0x2C) | SPI5_read(0x2D) << 8);

	// Sensitivity at 250 range = 8.75 mdps/digit
	s = 8.75 * 0.001;

	DataNow.OsX = (short) ((float) temp1 * s);
	DataNow.OsY = (short) ((float) temp2 * s);
	DataNow.OsZ = (short) ((float) temp3 * s);

}

void send_char(char c) {
	HAL_UART_Transmit(&huart1, (uint8_t*) &c, 1, 1000);
}

int __io_putchar(int ch) {
	send_char(ch);
	return ch;
}

/* USER CODE END 0 */

int main(void) {

	/* MCU Configuration--------------------------------------------------------*/

	/* Reset of all peripherals, Initializes the Flash interface and the Systick. */
	HAL_Init();

	/* Configure the system clock */
	SystemClock_Config();

	/* Initialize all configured peripherals */
	MX_GPIO_Init();
	MX_CRC_Init();
	MX_DMA2D_Init();
	MX_FMC_Init();
	MX_LTDC_Init();
	MX_SPI5_Init();
	MX_TIM1_Init();
	MX_USART1_UART_Init();
	MX_I2C3_Init();
	MX_TIM10_Init();
	MX_TIM11_Init();
	MX_GFXSIMULATOR_Init();
	/* USER CODE BEGIN 2 */

	__HAL_SPI_ENABLE(&hspi5);

	//Do testu*************
	LicznikPomocniczy = 0;
	LicznikPomocniczyRomberg = 0;
	//*********************

	//Poczatkowy stan gry**
	StanGry = Menu;
	StanMenu = NowaGra;
	ZmienionoStanMenu = 1;
	ZmienionoStanPoziomow = 1;
	WybranyPoziom = 0;
	RozpoczetoNowaGre = 0;
	CzyGra = 0;
	KontynuowanaGra = 0;
	Wygrana = 0;
	//*********************

	OpoznienieDodatniX = 0;
	OpoznienieDodatniY = 0;
	OpoznienieUjemnyX = 0;
	OpoznienieUjemnyY = 0;

	Animacja = 0;
	Direction = 1;
	X = 120;
	Y = 170;
	dT = 0.001;
	fMovedX = 0;
	fMovedY = 0;
	ResetTimeX = 0;
	ResetTimeY = 0;

	BSP_LCD_Init();
	//BSP_LCD_LayerDefaultInit(LCD_FOREGROUND_LAYER, LCD_FRAME_BUFFER+1024*1024*4);
	BSP_LCD_LayerDefaultInit(LCD_BACKGROUND_LAYER, LCD_FRAME_BUFFER);

	BSP_LCD_SelectLayer(LCD_BACKGROUND_LAYER);

	BSP_LCD_DisplayOn();
	BSP_LCD_Clear(LCD_COLOR_BLACK);

	//Zakomentowac po uruchomieniu menu
	//BSP_LCD_DrawBitmap(0, 0, (uint8_t*) image_data_Menu);
//  HAL_Delay(2000);
//  BSP_LCD_DrawBitmap(0, 0, (uint8_t*) image_data_Menu_nowagra);
//  HAL_Delay(2000);
//  BSP_LCD_DrawBitmap(0, 0, (uint8_t*) image_data_Menu_kontynuuj);
//  HAL_Delay(2000);
//  BSP_LCD_DrawBitmap(0, 0, (uint8_t*) image_data_Menu_poziomy);
//  //*********************************

	//BSP_LCD_SetTextColor(LCD_COLOR_DARKGRAY);
	//BSP_LCD_DisplayStringAtLine(5, (uint8_t*) "Hello");

	HAL_Delay(1000);
	BSP_LCD_ClearStringLine(5);

	BSP_LCD_Clear(LCD_COLOR_WHITE);

//  //Zakomentowac po uruchomieniu menu
//  BSP_LCD_SetTextColor(LCD_COLOR_BLACK);
//  BSP_LCD_FillRect(0, 0, 240, 15);
//  BSP_LCD_FillRect(0, 305, 240, 15);
//  BSP_LCD_FillRect(0, 15, 15, 290);
//  BSP_LCD_FillRect(225, 15, 15, 290);
	//*********************************

	if (BSP_GYRO_Init() == GYRO_ERROR) {
		printf("Nie udalo sie polaczyc z zyroskopem");
		HAL_Delay(10000);
	}

	czasZmiany = 0;
	HAL_TIM_Base_Start_IT(&htim10);
	HAL_TIM_Base_Start_IT(&htim11);

	//Zakomentuj przy sprawdzaniu menu !!!!!!!!!!!!!!!!!
//  Animacja = 1;
	//!!!!!!!!!!!!!!!!!!!!!!!!!!!!!!!!!!!!!!!!!!!!!!!!!!

	GPIO_PinState OdczytanyStanPrzycisku;

	/* USER CODE END 2 */

	/* Infinite loop */
	/* USER CODE BEGIN WHILE */
	while (1) {

		if (HAL_GetTick() - czasZmiany > 1500) {
			if (StanGry == Menu) {

				StanMenu = (StanMenu + 1) % 3;
				ZmienionoStanMenu = 1;

			} else if (StanGry == WyborPoziomu) {
				WybranyPoziom = (WybranyPoziom + 1) % 3;
				ZmienionoStanPoziomow = 1;
			}

			czasZmiany = HAL_GetTick();
		}
		//Sprawdzanie stanu przycisku*****************
		OdczytanyStanPrzycisku = HAL_GPIO_ReadPin(BB_GPIO_Port, BB_Pin);

		if (OdczytanyStanPrzycisku != PoprzedniStanPrzycisku) {
			PoprzedniCzasPrzycisku = HAL_GetTick();
		}

		if ((HAL_GetTick() - PoprzedniCzasPrzycisku) > 10) {
			if (OdczytanyStanPrzycisku != StanPrzycisku) {
				StanPrzycisku = OdczytanyStanPrzycisku;

				//  if (StanPrzycisku == GPIO_PIN_RESET) { //StanGry = Gra;
//                  if (StanGry == Menu) {
//                      StanMenu = (StanMenu + 1) % 3;
//                      ZmienionoStanMenu = 1;
//
//                  } else if (StanGry == WyborPoziomu) {
//                      WybranyPoziom = (WybranyPoziom + 1) % 3;
//                      ZmienionoStanPoziomow = 1;
//                  }
				//}

				//Przetestowac !!!!!!!!!!!!!!!!!
				//Jezeli przytrzymamy przycisk dluzej nastapi przejscie miedzy gra, a menu
				if (StanPrzycisku == GPIO_PIN_SET) {

					if (StanGry == Menu && StanMenu == NowaGra) {
						StanGry = Gra;
						RozpoczetoNowaGre = 1;
						CzyGra = 1;

					} else if (StanGry == Menu && StanMenu == KontynuujGre
							&& CzyGra == 1) {
						StanGry = Gra;
						KontynuowanaGra = 1;
					} else if (StanGry == Menu && StanMenu == ZmienPoziom) {
						StanGry = WyborPoziomu;
						WybranyPoziom = 0;
						ZmienionoStanPoziomow = 1;

					} else if (StanGry == WyborPoziomu) {
						StanGry = Menu;

					} else if (StanGry == Gra) {
						StanGry = Menu;
					}

					PoprzedniCzasPrzycisku = HAL_GetTick();

				}
			}
		}

		PoprzedniStanPrzycisku = OdczytanyStanPrzycisku;

		//Koniec sprawdzania stanu przycisku**********

		//Petla gry***********************************

		if (StanGry == Menu)

		{
			X_pri = 0;
			V_priX = 0;

			X_post = 0;
			V_postX = 0;

			Y_pri = 0;
			V_priY = 0;

			Y_post = 0;
			V_postY = 0;
			HAL_TIM_Base_Stop_IT(&htim11);
			if (ZmienionoStanMenu == 1) {
				switch (StanMenu) {
				case NowaGra:
					BSP_LCD_DrawBitmap(0, 0,
							(uint8_t*) image_data_Menu_nowagra);
					break;

				case KontynuujGre:
					BSP_LCD_DrawBitmap(0, 0,
							(uint8_t*) image_data_Menu_kontynuuj);
					break;

				case ZmienPoziom:

					BSP_LCD_DrawBitmap(0, 0,
							(uint8_t*) image_data_Menu_poziomy);
					break;
				}

				ZmienionoStanMenu = 0;
			}

		} else if (StanGry == WyborPoziomu) {
			if (ZmienionoStanPoziomow == 1) {
				switch (WybranyPoziom) {
				case 0:
					BSP_LCD_Clear(LCD_COLOR_WHITE);
					BSP_LCD_SetTextColor(LCD_COLOR_GREEN);
					BSP_LCD_FillRect(20, 20, 60, 60);
					BSP_LCD_DisplayChar(30, 30, 49);
					BSP_LCD_SetTextColor(LCD_COLOR_BLACK);

					BSP_LCD_FillRect(90, 20, 60, 60);
					BSP_LCD_DisplayChar(100, 30, 50);

					BSP_LCD_FillRect(160, 20, 60, 60);
					BSP_LCD_DisplayChar(170, 30, 51);
					break;

				case 1:
					BSP_LCD_Clear(LCD_COLOR_WHITE);
					BSP_LCD_SetTextColor(LCD_COLOR_BLACK);
					BSP_LCD_FillRect(20, 20, 60, 60);
					BSP_LCD_DisplayChar(30, 30, 49);

					BSP_LCD_SetTextColor(LCD_COLOR_GREEN);
					BSP_LCD_FillRect(90, 20, 60, 60);
					BSP_LCD_DisplayChar(100, 30, 50);

					BSP_LCD_SetTextColor(LCD_COLOR_BLACK);
					BSP_LCD_FillRect(160, 20, 60, 60);
					BSP_LCD_DisplayChar(170, 30, 51);
					break;

				case 2:
					BSP_LCD_Clear(LCD_COLOR_WHITE);
					BSP_LCD_SetTextColor(LCD_COLOR_BLACK);
					BSP_LCD_FillRect(20, 20, 60, 60);
					BSP_LCD_DisplayChar(30, 30, 49);

					BSP_LCD_SetTextColor(LCD_COLOR_BLACK);
					BSP_LCD_FillRect(90, 20, 60, 60);
					BSP_LCD_DisplayChar(100, 30, 50);

					BSP_LCD_SetTextColor(LCD_COLOR_GREEN);
					BSP_LCD_FillRect(160, 20, 60, 60);
					BSP_LCD_DisplayChar(170, 30, 51);
					break;

				default:
					break;
				}

				ZmienionoStanPoziomow = 0;
			}

		} else if (StanGry == Gra) {
			HAL_TIM_Base_Start_IT(&htim11);

			if (Wygrana == 1) {
				HAL_TIM_Base_Stop_IT(&htim11);
				BSP_LCD_Clear(LCD_COLOR_WHITE);
				BSP_LCD_SetTextColor(LCD_COLOR_RED);
				BSP_LCD_DisplayStringAt(10, 30, (uint8_t*) "WYGRANA",
						CENTER_MODE);

				BSP_LCD_SetTextColor(LCD_COLOR_WHITE);

				HAL_Delay(2000);

				WybranyPoziom = (WybranyPoziom + 1) % 3;
				RozpoczetoNowaGre = 1;
				Wygrana = 0;
				X_pri = 0;
				V_priX = 0;

				X_post = 0;
				V_postX = 0;

				Y_pri = 0;
				V_priY = 0;

				Y_post = 0;
				V_postY = 0;
				HAL_TIM_Base_Start_IT(&htim11);
			}

			if (WybranyPoziom == 0 && RozpoczetoNowaGre == 1) {
				BSP_LCD_Clear(LCD_COLOR_BLACK);
				BSP_LCD_SetTextColor(LCD_COLOR_WHITE);

				for (uint32_t i = 1; i <= IloscPunktowSciezki1; i++) {
					if (PunktySciezki1[i].SasiedniePunkty[0] != 0) {
						for (int j = -6; j < 7; j++) {
							BSP_LCD_DrawLine(PunktySciezki1[i].X - 6,
									PunktySciezki1[i].Y + j,
									PunktySciezki1[PunktySciezki1[i].SasiedniePunkty[0]].X
											+ 6,
									PunktySciezki1[PunktySciezki1[i].SasiedniePunkty[0]].Y
											+ j);
						}

					}

					if (PunktySciezki1[i].SasiedniePunkty[2] != 0) {
						for (int j = -6; j < 7; j++) {
							BSP_LCD_DrawLine(PunktySciezki1[i].X + j,
									PunktySciezki1[i].Y - 6,
									PunktySciezki1[PunktySciezki1[i].SasiedniePunkty[2]].X
											+ j,
									PunktySciezki1[PunktySciezki1[i].SasiedniePunkty[2]].Y
											+ 6);
						}
					}
				}

				PozycjaNaSciezce = 1;

				BSP_LCD_SetTextColor(LCD_COLOR_RED);

				BSP_LCD_FillCircle(PunktySciezki1[PozycjaNaSciezce].X,
						PunktySciezki1[PozycjaNaSciezce].Y, 5);

				X = PunktySciezki1[PozycjaNaSciezce].X;
				Y = PunktySciezki1[PozycjaNaSciezce].Y;

				PoprzednieX = X;
				PoprzednieY = Y;

				BSP_LCD_SetTextColor(LCD_COLOR_CYAN);
				BSP_LCD_FillRect(PunktySciezki1[IloscPunktowSciezki1].X - 6,
						PunktySciezki1[IloscPunktowSciezki1].Y - 6, 13, 13);

				BSP_LCD_SetTextColor(LCD_COLOR_WHITE);

				RozpoczetoNowaGre = 0;

			} else if (WybranyPoziom == 1 && RozpoczetoNowaGre == 1) {
				BSP_LCD_Clear(LCD_COLOR_BLACK);
				BSP_LCD_SetTextColor(LCD_COLOR_WHITE);

				for (uint32_t i = 1; i <= IloscPunktowSciezki2; i++) {
					if (PunktySciezki2[i].SasiedniePunkty[0] != 0) {
						for (int j = -6; j < 7; j++) {
							BSP_LCD_DrawLine(PunktySciezki2[i].X - 6,
									PunktySciezki2[i].Y + j,
									PunktySciezki2[PunktySciezki2[i].SasiedniePunkty[0]].X
											+ 6,
									PunktySciezki2[PunktySciezki2[i].SasiedniePunkty[0]].Y
											+ j);
						}

					}

					if (PunktySciezki2[i].SasiedniePunkty[2] != 0) {
						for (int j = -6; j < 7; j++) {
							BSP_LCD_DrawLine(PunktySciezki2[i].X + j,
									PunktySciezki2[i].Y - 6,
									PunktySciezki2[PunktySciezki2[i].SasiedniePunkty[2]].X
											+ j,
									PunktySciezki2[PunktySciezki2[i].SasiedniePunkty[2]].Y
											+ 6);
						}
					}
				}

				PozycjaNaSciezce = 1;

				BSP_LCD_SetTextColor(LCD_COLOR_RED);

				BSP_LCD_FillCircle(PunktySciezki2[PozycjaNaSciezce].X,
						PunktySciezki2[PozycjaNaSciezce].Y, 5);

				X = PunktySciezki2[PozycjaNaSciezce].X;
				Y = PunktySciezki2[PozycjaNaSciezce].Y;

				PoprzednieX = X;
				PoprzednieY = Y;

				BSP_LCD_SetTextColor(LCD_COLOR_CYAN);
				BSP_LCD_FillRect(PunktySciezki2[IloscPunktowSciezki2].X - 6,
						PunktySciezki2[IloscPunktowSciezki2].Y - 6, 13, 13);

				BSP_LCD_SetTextColor(LCD_COLOR_WHITE);

				RozpoczetoNowaGre = 0;

			} else if (WybranyPoziom == 2 && RozpoczetoNowaGre == 1) {
				BSP_LCD_Clear(LCD_COLOR_BLACK);
				BSP_LCD_SetTextColor(LCD_COLOR_WHITE);

				for (uint32_t i = 1; i <= IloscPunktowSciezki3; i++) {
					if (PunktySciezki3[i].SasiedniePunkty[0] != 0) {
						for (int j = -6; j < 7; j++) {
							BSP_LCD_DrawLine(PunktySciezki3[i].X - 6,
									PunktySciezki3[i].Y + j,
									PunktySciezki3[PunktySciezki3[i].SasiedniePunkty[0]].X
											+ 6,
									PunktySciezki3[PunktySciezki3[i].SasiedniePunkty[0]].Y
											+ j);
						}

					}

					if (PunktySciezki3[i].SasiedniePunkty[2] != 0) {
						for (int j = -6; j < 7; j++) {
							BSP_LCD_DrawLine(PunktySciezki3[i].X + j,
									PunktySciezki3[i].Y - 6,
									PunktySciezki3[PunktySciezki3[i].SasiedniePunkty[2]].X
											+ j,
									PunktySciezki3[PunktySciezki3[i].SasiedniePunkty[2]].Y
											+ 6);
						}
					}
				}

				PozycjaNaSciezce = 1;

				BSP_LCD_SetTextColor(LCD_COLOR_RED);

				BSP_LCD_FillCircle(PunktySciezki3[PozycjaNaSciezce].X,
						PunktySciezki3[PozycjaNaSciezce].Y, 5);

				X = PunktySciezki3[PozycjaNaSciezce].X;
				Y = PunktySciezki3[PozycjaNaSciezce].Y;

				PoprzednieX = X;
				PoprzednieY = Y;

				BSP_LCD_SetTextColor(LCD_COLOR_CYAN);
				BSP_LCD_FillRect(PunktySciezki3[IloscPunktowSciezki3].X - 6,
						PunktySciezki3[IloscPunktowSciezki3].Y - 6, 13, 13);

				BSP_LCD_SetTextColor(LCD_COLOR_WHITE);

				RozpoczetoNowaGre = 0;

			} else if (WybranyPoziom == 0 && KontynuowanaGra == 1) {
				BSP_LCD_Clear(LCD_COLOR_BLACK);
				BSP_LCD_SetTextColor(LCD_COLOR_WHITE);

				for (uint32_t i = 1; i <= IloscPunktowSciezki1; i++) {
					if (PunktySciezki1[i].SasiedniePunkty[0] != 0) {
						for (int j = -6; j < 7; j++) {
							BSP_LCD_DrawLine(PunktySciezki1[i].X - 6,
									PunktySciezki1[i].Y + j,
									PunktySciezki1[PunktySciezki1[i].SasiedniePunkty[0]].X
											+ 6,
									PunktySciezki1[PunktySciezki1[i].SasiedniePunkty[0]].Y
											+ j);
						}

					}

					if (PunktySciezki1[i].SasiedniePunkty[2] != 0) {
						for (int j = -6; j < 7; j++) {
							BSP_LCD_DrawLine(PunktySciezki1[i].X + j,
									PunktySciezki1[i].Y - 6,
									PunktySciezki1[PunktySciezki1[i].SasiedniePunkty[2]].X
											+ j,
									PunktySciezki1[PunktySciezki1[i].SasiedniePunkty[2]].Y
											+ 6);
						}
					}
				}

				BSP_LCD_SetTextColor(LCD_COLOR_RED);

				//BSP_LCD_FillCircle(PunktySciezki1[PozycjaNaSciezce].X, PunktySciezki1[PozycjaNaSciezce].Y, 5);

				BSP_LCD_SetTextColor(LCD_COLOR_CYAN);
				BSP_LCD_FillRect(PunktySciezki1[IloscPunktowSciezki1].X - 6,
						PunktySciezki1[IloscPunktowSciezki1].Y - 6, 13, 13);

				BSP_LCD_SetTextColor(LCD_COLOR_WHITE);

				KontynuowanaGra = 0;

			} else if (WybranyPoziom == 1 && KontynuowanaGra == 1) {
				BSP_LCD_Clear(LCD_COLOR_BLACK);
				BSP_LCD_SetTextColor(LCD_COLOR_WHITE);

				for (uint32_t i = 1; i <= IloscPunktowSciezki2; i++) {
					if (PunktySciezki2[i].SasiedniePunkty[0] != 0) {
						for (int j = -6; j < 7; j++) {
							BSP_LCD_DrawLine(PunktySciezki2[i].X - 6,
									PunktySciezki2[i].Y + j,
									PunktySciezki2[PunktySciezki2[i].SasiedniePunkty[0]].X
											+ 6,
									PunktySciezki2[PunktySciezki2[i].SasiedniePunkty[0]].Y
											+ j);
						}

					}

					if (PunktySciezki2[i].SasiedniePunkty[2] != 0) {
						for (int j = -6; j < 7; j++) {
							BSP_LCD_DrawLine(PunktySciezki2[i].X + j,
									PunktySciezki2[i].Y - 6,
									PunktySciezki2[PunktySciezki2[i].SasiedniePunkty[2]].X
											+ j,
									PunktySciezki2[PunktySciezki2[i].SasiedniePunkty[2]].Y
											+ 6);
						}
					}
				}

				BSP_LCD_SetTextColor(LCD_COLOR_RED);

				//BSP_LCD_FillCircle(PunktySciezki2[PozycjaNaSciezce].X, PunktySciezki2[PozycjaNaSciezce].Y, 5);

				BSP_LCD_SetTextColor(LCD_COLOR_CYAN);
				BSP_LCD_FillRect(PunktySciezki2[IloscPunktowSciezki2].X - 6,
						PunktySciezki2[IloscPunktowSciezki2].Y - 6, 13, 13);

				BSP_LCD_SetTextColor(LCD_COLOR_WHITE);

				KontynuowanaGra = 0;

			} else if (WybranyPoziom == 2 && KontynuowanaGra == 1) {
				BSP_LCD_Clear(LCD_COLOR_BLACK);
				BSP_LCD_SetTextColor(LCD_COLOR_WHITE);

				for (uint32_t i = 1; i <= IloscPunktowSciezki3; i++) {
					if (PunktySciezki3[i].SasiedniePunkty[0] != 0) {
						for (int j = -6; j < 7; j++) {
							BSP_LCD_DrawLine(PunktySciezki3[i].X - 6,
									PunktySciezki3[i].Y + j,
									PunktySciezki3[PunktySciezki3[i].SasiedniePunkty[0]].X
											+ 6,
									PunktySciezki3[PunktySciezki3[i].SasiedniePunkty[0]].Y
											+ j);
						}

					}

					if (PunktySciezki3[i].SasiedniePunkty[2] != 0) {
						for (int j = -6; j < 7; j++) {
							BSP_LCD_DrawLine(PunktySciezki3[i].X + j,
									PunktySciezki3[i].Y - 6,
									PunktySciezki3[PunktySciezki3[i].SasiedniePunkty[2]].X
											+ j,
									PunktySciezki3[PunktySciezki3[i].SasiedniePunkty[2]].Y
											+ 6);
						}
					}
				}

				BSP_LCD_SetTextColor(LCD_COLOR_RED);

				//BSP_LCD_FillCircle(PunktySciezki3[PozycjaNaSciezce].X, PunktySciezki3[PozycjaNaSciezce].Y, 5);

				BSP_LCD_SetTextColor(LCD_COLOR_CYAN);
				BSP_LCD_FillRect(PunktySciezki3[IloscPunktowSciezki3].X - 6,
						PunktySciezki3[IloscPunktowSciezki3].Y - 6, 13, 13);

				BSP_LCD_SetTextColor(LCD_COLOR_WHITE);

				KontynuowanaGra = 0;
			}

		}

		//Koniec petli gry****************************
//
//        printf("Angle X: %li\n\r", AngleX);
//        printf("Angle Y: %li\n\r", AngleY);
//        printf("Angle Z: %li\n\r", AngleZ);
//        printf("CzasX: %d\n\r", ResetTimeX);
//        printf("CzasY: %d\n\r", ResetTimeY);
//        printf("Predkosc X: %d\n\r", DataNow.OsX);
//        printf("Predkosc Y: %d\n\r", DataNow.OsY);

		//Do testu************************************
		/*printf("CalkaTrap X: %li\n\r", CalkaTrapX);
		 printf("CalkaTrap Y: %li\n\r", CalkaTrapY);

		 printf("CalkaRicha X: %li\n\r", CalkaRichaX);
		 printf("CalkaRicha Y: %li\n\r", CalkaRichaY);*/

		//printf("CalkaRomb X: %li\n\r", CalkaRombX);
		//printf("CalkaRomb Y: %li\n\r", CalkaRombY);
		//********************************************
		//printf("OsX: %d\n\r", Data.OsX);
		//printf("OsY: %d\n\r", Data.OsY);
		//printf("OsZ: %d\n\r", Data.OsZ);
		//HAL_Delay(200);
		/* USER CODE END WHILE */

	}
}

void SystemClock_Config(void) {
	RCC_OscInitTypeDef RCC_OscInitStruct = { 0 };
	RCC_ClkInitTypeDef RCC_ClkInitStruct = { 0 };
	RCC_PeriphCLKInitTypeDef PeriphClkInitStruct = { 0 };

	/** Configure the main internal regulator output voltage
	 */
	__HAL_RCC_PWR_CLK_ENABLE()
	;
	__HAL_PWR_VOLTAGESCALING_CONFIG(PWR_REGULATOR_VOLTAGE_SCALE1);
	/** Initializes the CPU, AHB and APB busses clocks
	 */
	RCC_OscInitStruct.OscillatorType = RCC_OSCILLATORTYPE_HSE;
	RCC_OscInitStruct.HSEState = RCC_HSE_ON;
	RCC_OscInitStruct.PLL.PLLState = RCC_PLL_ON;
	RCC_OscInitStruct.PLL.PLLSource = RCC_PLLSOURCE_HSE;
	RCC_OscInitStruct.PLL.PLLM = 4;
	RCC_OscInitStruct.PLL.PLLN = 180;
	RCC_OscInitStruct.PLL.PLLP = RCC_PLLP_DIV2;
	RCC_OscInitStruct.PLL.PLLQ = 3;
	if (HAL_RCC_OscConfig(&RCC_OscInitStruct) != HAL_OK) {
		Error_Handler();
	}
	/** Activate the Over-Drive mode
	 */
	if (HAL_PWREx_EnableOverDrive() != HAL_OK) {
		Error_Handler();
	}
	/** Initializes the CPU, AHB and APB busses clocks
	 */
	RCC_ClkInitStruct.ClockType = RCC_CLOCKTYPE_HCLK | RCC_CLOCKTYPE_SYSCLK
			| RCC_CLOCKTYPE_PCLK1 | RCC_CLOCKTYPE_PCLK2;
	RCC_ClkInitStruct.SYSCLKSource = RCC_SYSCLKSOURCE_PLLCLK;
	RCC_ClkInitStruct.AHBCLKDivider = RCC_SYSCLK_DIV1;
	RCC_ClkInitStruct.APB1CLKDivider = RCC_HCLK_DIV4;
	RCC_ClkInitStruct.APB2CLKDivider = RCC_HCLK_DIV2;

	if (HAL_RCC_ClockConfig(&RCC_ClkInitStruct, FLASH_LATENCY_5) != HAL_OK) {
		Error_Handler();
	}
	PeriphClkInitStruct.PeriphClockSelection = RCC_PERIPHCLK_LTDC;
	PeriphClkInitStruct.PLLSAI.PLLSAIN = 192;
	PeriphClkInitStruct.PLLSAI.PLLSAIR = 2;
	PeriphClkInitStruct.PLLSAIDivR = RCC_PLLSAIDIVR_2;
	if (HAL_RCCEx_PeriphCLKConfig(&PeriphClkInitStruct) != HAL_OK) {
		Error_Handler();
	}
}

void HAL_TIM_PeriodElapsedCallback(TIM_HandleTypeDef *htim) {
	/* USER CODE BEGIN Callback 0 */
	if (htim->Instance == TIM10) //Przerwanie pochodzi od timera 10
	{
		;
	}

	if (htim->Instance == TIM11) {
		OurL3GD20_Read();
		if (DataNow.OsX < 10 && DataNow.OsX > -10) {
			DataNow.OsX = 0;
			V_postX = 0;

		}

		if (DataNow.OsY < 10 && DataNow.OsY > -10) {
			DataNow.OsY = 0;
			V_postY = 0;
		}

		if (DataNow.OsZ < 10 && DataNow.OsZ > -10)
			DataNow.OsZ = 0;

		X_pri = X_post + (int32_t) (0.4 * V_postX);
		V_priX = V_postX;

		X_post = X_pri + (int32_t) (0.9 * (DataNow.OsX - V_priX) * 0.4);
		V_postX = V_priX + (int32_t) (0.05 * (DataNow.OsX - V_priX));

		Y_pri = Y_post + (int32_t) (0.4 * V_postY);
		V_priY = V_postY;

		Y_post = Y_pri + (int32_t) (0.9 * (DataNow.OsY - V_priY) * 0.4);
		V_postY = V_priY + (int32_t) (0.05 * (DataNow.OsY - V_priY));

		//To mozna wsumie przy testowaniu wywalic za czesc testowa
		if ((DataNow.OsX >= 25 && DataNow.OsY <= 20)
				|| (DataNow.OsX <= -25 && DataNow.OsY >= -20))
			AngleX +=
					(long) (DataNow.OsX + ((DataOld.OsX - DataNow.OsX) * 0.5));
		else if ((DataNow.OsX >= 25 && DataNow.OsY >= 25)
				|| (DataNow.OsX <= -25 && DataNow.OsY <= -25))
			AngleX +=
					(long) (DataNow.OsX + ((DataOld.OsX - DataNow.OsX) * 0.5));

		if ((DataNow.OsY >= 25 && DataNow.OsX <= 20)
				|| (DataNow.OsY <= -25 && DataNow.OsX >= -20))
			AngleY +=
					(long) (DataNow.OsY + ((DataOld.OsY - DataNow.OsY) * 0.5));
		else if ((DataNow.OsX >= 25 && DataNow.OsY >= 25)
				|| (DataNow.OsX <= -25 && DataNow.OsY <= -25))
			AngleY +=
					(long) (DataNow.OsY + ((DataOld.OsY - DataNow.OsY) * 0.5));

//*************TESTOWA CZESC*****************************************************************************************

		/*//Liczenie calki metoda wietu trapezow
		 CalkaTrapX += (long) (4 * ((DataOld.OsX + DataNow.OsX) * 0.5)); //Czas miedzy kolejnymi pomiarami rowny 0.004 s, pomnozony przez 1000 zeby nie miec liczby z przecinkiem
		 CalkaTrapY += (long) (4 * ((DataOld.OsY + DataNow.OsY) * 0.5));
		 //koniec

		 //Liczenie calki za pomoca ekstrapolacji Richardsona
		 if (LicznikPomocniczy == 0) {
		 CalkaPosrednia2X = (long) (4 * ((DataOld.OsX + DataNow.OsX) * 0.5));
		 CalkaPosrednia2Y = (long) (4 * ((DataOld.OsY + DataNow.OsY) * 0.5));

		 DataTempRich = DataOld;

		 LicznikPomocniczy = 1;

		 } else {
		 CalkaPosrednia2X +=
		 (long) (4 * ((DataOld.OsX + DataNow.OsX) * 0.5));
		 CalkaPosrednia2Y +=
		 (long) (4 * ((DataOld.OsY + DataNow.OsY) * 0.5));

		 CalkaPosrednia1X = (long) (8
		 * ((DataTempRich.OsX + DataNow.OsX) * 0.5));
		 CalkaPosrednia1Y = (long) (8
		 * ((DataTempRich.OsY + DataNow.OsY) * 0.5));

		 CalkaRichaX += (long) (CalkaPosrednia2X)
		 + ((CalkaPosrednia2X - CalkaPosrednia1X) / 3);
		 CalkaRichaY += (long) (CalkaPosrednia2Y)
		 + ((CalkaPosrednia2Y - CalkaPosrednia1Y) / 3);
		 LicznikPomocniczy = 0;
		 }
		 */
		//koniec
		//Liczenie calki za pomoca metody Romberga
		if (LicznikPomocniczyRomberg == 0) {
			DataTempRom[0] = DataOld;

			CalkaPosredniaRomX[3] = (long) (4
					* ((DataOld.OsX + DataNow.OsX) * 0.5));
			CalkaPosredniaRomY[3] = (long) (4
					* ((DataOld.OsY + DataNow.OsY) * 0.5));

			LicznikPomocniczyRomberg = 1;

		} else if (LicznikPomocniczyRomberg == 1) {
			CalkaPosredniaRomX[3] += (long) (4
					* ((DataOld.OsX + DataNow.OsX) * 0.5));
			CalkaPosredniaRomY[3] += (long) (4
					* ((DataOld.OsY + DataNow.OsY) * 0.5));

			CalkaPosredniaRomX[2] = (long) (8
					* ((DataTempRom[0].OsX + DataNow.OsX) * 0.5));
			CalkaPosredniaRomY[2] = (long) (8
					* ((DataTempRom[0].OsY + DataNow.OsY) * 0.5));

			LicznikPomocniczyRomberg = 2;

		} else if (LicznikPomocniczyRomberg == 2) {
			DataTempRom[2] = DataOld;

			CalkaPosredniaRomX[3] += (long) (4
					* ((DataOld.OsX + DataNow.OsX) * 0.5));
			CalkaPosredniaRomY[3] += (long) (4
					* ((DataOld.OsY + DataNow.OsY) * 0.5));

			LicznikPomocniczyRomberg = 3;

		} else if (LicznikPomocniczyRomberg == 3) {
			CalkaPosredniaRomX[3] += (long) (4
					* ((DataOld.OsX + DataNow.OsX) * 0.5));
			CalkaPosredniaRomY[3] += (long) (4
					* ((DataOld.OsY + DataNow.OsY) * 0.5));

			CalkaPosredniaRomX[2] += (long) (8
					* ((DataTempRom[2].OsX + DataNow.OsX) * 0.5));
			CalkaPosredniaRomY[2] += (long) (8
					* ((DataTempRom[2].OsY + DataNow.OsY) * 0.5));

			CalkaPosredniaRomX[1] = (long) (16
					* ((DataTempRom[0].OsX + DataNow.OsX) * 0.5));
			CalkaPosredniaRomY[1] = (long) (16
					* ((DataTempRom[0].OsY + DataNow.OsY) * 0.5));

			LicznikPomocniczyRomberg = 4;

		} else if (LicznikPomocniczyRomberg == 4) {
			DataTempRom[1] = DataOld;

			CalkaPosredniaRomX[3] += (long) (4
					* ((DataOld.OsX + DataNow.OsX) * 0.5));
			CalkaPosredniaRomY[3] += (long) (4
					* ((DataOld.OsY + DataNow.OsY) * 0.5));

			LicznikPomocniczyRomberg = 5;

		} else if (LicznikPomocniczyRomberg == 5) {
			CalkaPosredniaRomX[3] += (long) (4
					* ((DataOld.OsX + DataNow.OsX) * 0.5));
			CalkaPosredniaRomY[3] += (long) (4
					* ((DataOld.OsY + DataNow.OsY) * 0.5));

			CalkaPosredniaRomX[2] += (long) (8
					* ((DataTempRom[1].OsX + DataNow.OsX) * 0.5));
			CalkaPosredniaRomY[2] += (long) (8
					* ((DataTempRom[1].OsY + DataNow.OsY) * 0.5));

			LicznikPomocniczyRomberg = 6;

		} else if (LicznikPomocniczyRomberg == 6) {
			DataTempRom[3] = DataOld;

			CalkaPosredniaRomX[3] += (long) (4
					* ((DataOld.OsX + DataNow.OsX) * 0.5));
			CalkaPosredniaRomY[3] += (long) (4
					* ((DataOld.OsY + DataNow.OsY) * 0.5));

			LicznikPomocniczyRomberg = 7;

		} else if (LicznikPomocniczyRomberg == 7) {
			CalkaPosredniaRomX[3] += (long) (4
					* ((DataOld.OsX + DataNow.OsX) * 0.5));
			CalkaPosredniaRomY[3] += (long) (4
					* ((DataOld.OsY + DataNow.OsY) * 0.5));

			CalkaPosredniaRomX[2] += (long) (8
					* ((DataTempRom[3].OsX + DataNow.OsX) * 0.5));
			CalkaPosredniaRomY[2] += (long) (8
					* ((DataTempRom[3].OsY + DataNow.OsY) * 0.5));

			CalkaPosredniaRomX[1] += (long) (16
					* ((DataTempRom[1].OsX + DataNow.OsX) * 0.5));
			CalkaPosredniaRomY[1] += (long) (16
					* ((DataTempRom[1].OsY + DataNow.OsY) * 0.5));

			CalkaPosredniaRomX[0] = (long) (32
					* ((DataTempRom[0].OsX + DataNow.OsX) * 0.5));
			CalkaPosredniaRomY[0] = (long) (32
					* ((DataTempRom[0].OsY + DataNow.OsY) * 0.5));

			CalkaPomocniczaRomX[0] = (long) (CalkaPosredniaRomX[1]
					+ ((CalkaPosredniaRomX[1] - CalkaPosredniaRomX[0]) / 3));
			CalkaPomocniczaRomX[1] = (long) (CalkaPosredniaRomX[2]
					+ ((CalkaPosredniaRomX[2] - CalkaPosredniaRomX[1]) / 3));
			CalkaPomocniczaRomX[2] = (long) (CalkaPosredniaRomX[3]
					+ ((CalkaPosredniaRomX[3] - CalkaPosredniaRomX[2]) / 3));

			CalkaPomocniczaRomY[0] = (long) (CalkaPosredniaRomY[1]
					+ ((CalkaPosredniaRomY[1] - CalkaPosredniaRomY[0]) / 3));
			CalkaPomocniczaRomY[1] = (long) (CalkaPosredniaRomY[2]
					+ ((CalkaPosredniaRomY[2] - CalkaPosredniaRomY[1]) / 3));
			CalkaPomocniczaRomY[2] = (long) (CalkaPosredniaRomY[3]
					+ ((CalkaPosredniaRomY[3] - CalkaPosredniaRomY[2]) / 3));

			CalkaPomocnicza2RomX[0] = (long) (CalkaPomocniczaRomX[1]
					+ ((CalkaPomocniczaRomX[1] - CalkaPomocniczaRomX[0]) / 15));
			CalkaPomocnicza2RomX[1] = (long) (CalkaPomocniczaRomX[2]
					+ ((CalkaPomocniczaRomX[2] - CalkaPomocniczaRomX[1]) / 15));

			CalkaPomocnicza2RomY[0] = (long) (CalkaPomocniczaRomY[1]
					+ ((CalkaPomocniczaRomY[1] - CalkaPomocniczaRomY[0]) / 15));
			CalkaPomocnicza2RomY[1] = (long) (CalkaPomocniczaRomY[2]
					+ ((CalkaPomocniczaRomY[2] - CalkaPomocniczaRomY[1]) / 15));

			CalkaRombX +=
					(long) (CalkaPomocnicza2RomX[1]
							+ ((CalkaPomocnicza2RomX[1]
									- CalkaPomocnicza2RomX[0]) / 63));
			CalkaRombY +=
					(long) (CalkaPomocnicza2RomY[1]
							+ ((CalkaPomocnicza2RomY[1]
									- CalkaPomocnicza2RomY[0]) / 63));

			LicznikPomocniczyRomberg = 0;
		}
		//koniec

//*************KONIEC TESTOWEJ CZESCI*****************************************************************************************

		DataOld = DataNow;
// movement of the ball
		if (Y_post > 5000) //bylo 10000
				{
			fMovedX = 1;
			fMovedY = 1;

			/*if (X < 215)
			 X += 1;*/

			if (WybranyPoziom == 0) {
				if (PunktySciezki1[PozycjaNaSciezce].SasiedniePunkty[0] != 0
						&& X
								< PunktySciezki1[PunktySciezki1[PozycjaNaSciezce].SasiedniePunkty[0]].X
						&& Y
								== PunktySciezki1[PunktySciezki1[PozycjaNaSciezce].SasiedniePunkty[0]].Y) {
					if (OpoznienieDodatniX > SPOWOLNIENIE_KULKI) {
						PoprzednieX = X;
						X += 1;
						if (X
								== PunktySciezki1[PunktySciezki1[PozycjaNaSciezce].SasiedniePunkty[0]].X) {
							PozycjaNaSciezce =
									PunktySciezki1[PunktySciezki1[PozycjaNaSciezce].SasiedniePunkty[0]].NumerPunktu;

							if (PozycjaNaSciezce == IloscPunktowSciezki1) {
								Wygrana = 1;
							}
						}

						OpoznienieDodatniX = 0;
					}

					OpoznienieDodatniX += 1;
				}

			} else if (WybranyPoziom == 1) {
				if (PunktySciezki2[PozycjaNaSciezce].SasiedniePunkty[0] != 0
						&& X
								< PunktySciezki2[PunktySciezki2[PozycjaNaSciezce].SasiedniePunkty[0]].X
						&& Y
								== PunktySciezki2[PunktySciezki2[PozycjaNaSciezce].SasiedniePunkty[0]].Y) {
					if (OpoznienieDodatniX > SPOWOLNIENIE_KULKI) {
						PoprzednieX = X;
						X += 1;
						if (X
								== PunktySciezki2[PunktySciezki2[PozycjaNaSciezce].SasiedniePunkty[0]].X) {
							PozycjaNaSciezce =
									PunktySciezki2[PunktySciezki2[PozycjaNaSciezce].SasiedniePunkty[0]].NumerPunktu;

							if (PozycjaNaSciezce == IloscPunktowSciezki2) {
								Wygrana = 1;
							}
						}

						OpoznienieDodatniX = 0;
					}

					OpoznienieDodatniX += 1;
				}

			} else if (WybranyPoziom == 2) {
				if (PunktySciezki3[PozycjaNaSciezce].SasiedniePunkty[0] != 0
						&& X
								< PunktySciezki3[PunktySciezki3[PozycjaNaSciezce].SasiedniePunkty[0]].X
						&& Y
								== PunktySciezki3[PunktySciezki3[PozycjaNaSciezce].SasiedniePunkty[0]].Y) {
					if (OpoznienieDodatniX > SPOWOLNIENIE_KULKI) {
						PoprzednieX = X;
						X += 1;
						if (X
								== PunktySciezki3[PunktySciezki3[PozycjaNaSciezce].SasiedniePunkty[0]].X) {
							PozycjaNaSciezce =
									PunktySciezki3[PunktySciezki3[PozycjaNaSciezce].SasiedniePunkty[0]].NumerPunktu;

							if (PozycjaNaSciezce == IloscPunktowSciezki3) {
								Wygrana = 1;
							}
						}

						OpoznienieDodatniX = 0;
					}

					OpoznienieDodatniX += 1;
				}
			}

		} else if (Y_post < -5000) //bylo -10000
				{
			fMovedX = 1;
			fMovedY = 1;

			/*if (X > 25)
			 X -= 1;*/

			if (WybranyPoziom == 0) {
				if (PunktySciezki1[PozycjaNaSciezce].SasiedniePunkty[1] != 0
						&& X
								> PunktySciezki1[PunktySciezki1[PozycjaNaSciezce].SasiedniePunkty[1]].X
						&& Y
								== PunktySciezki1[PunktySciezki1[PozycjaNaSciezce].SasiedniePunkty[1]].Y) {
					if (OpoznienieUjemnyX > SPOWOLNIENIE_KULKI) {
						PoprzednieX = X;
						X -= 1;
						if (X
								== PunktySciezki1[PunktySciezki1[PozycjaNaSciezce].SasiedniePunkty[1]].X) {
							PozycjaNaSciezce =
									PunktySciezki1[PunktySciezki1[PozycjaNaSciezce].SasiedniePunkty[1]].NumerPunktu;

							if (PozycjaNaSciezce == IloscPunktowSciezki1) {
								Wygrana = 1;
							}
						}

						OpoznienieUjemnyX = 0;
					}

					OpoznienieUjemnyX += 1;
				}

			} else if (WybranyPoziom == 1) {
				if (PunktySciezki2[PozycjaNaSciezce].SasiedniePunkty[1] != 0
						&& X
								> PunktySciezki2[PunktySciezki2[PozycjaNaSciezce].SasiedniePunkty[1]].X
						&& Y
								== PunktySciezki2[PunktySciezki2[PozycjaNaSciezce].SasiedniePunkty[1]].Y) {
					if (OpoznienieUjemnyX > SPOWOLNIENIE_KULKI) {
						PoprzednieX = X;
						X -= 1;
						if (X
								== PunktySciezki2[PunktySciezki2[PozycjaNaSciezce].SasiedniePunkty[1]].X) {
							PozycjaNaSciezce =
									PunktySciezki2[PunktySciezki2[PozycjaNaSciezce].SasiedniePunkty[1]].NumerPunktu;

							if (PozycjaNaSciezce == IloscPunktowSciezki2) {
								Wygrana = 1;
							}

						}

						OpoznienieUjemnyX = 0;
					}

					OpoznienieUjemnyX += 1;

				}

			} else if (WybranyPoziom == 2) {
				if (PunktySciezki3[PozycjaNaSciezce].SasiedniePunkty[1] != 0
						&& X
								> PunktySciezki3[PunktySciezki3[PozycjaNaSciezce].SasiedniePunkty[1]].X
						&& Y
								== PunktySciezki3[PunktySciezki3[PozycjaNaSciezce].SasiedniePunkty[1]].Y) {
					if (OpoznienieUjemnyX > SPOWOLNIENIE_KULKI) {
						PoprzednieX = X;
						X -= 1;
						if (X
								== PunktySciezki3[PunktySciezki3[PozycjaNaSciezce].SasiedniePunkty[1]].X) {
							PozycjaNaSciezce =
									PunktySciezki3[PunktySciezki3[PozycjaNaSciezce].SasiedniePunkty[1]].NumerPunktu;

							if (PozycjaNaSciezce == IloscPunktowSciezki3) {
								Wygrana = 1;
							}

						}

						OpoznienieUjemnyX = 0;
					}

					OpoznienieUjemnyX += 1;
				}
			}
		}

		if (X_post > 5000) //bylo 10000
				{
			fMovedX = 1;
			fMovedY = 1;

			/*if (Y < 295)
			 Y += 1;*/

			if (WybranyPoziom == 0) {
				if (PunktySciezki1[PozycjaNaSciezce].SasiedniePunkty[2] != 0
						&& Y
								< PunktySciezki1[PunktySciezki1[PozycjaNaSciezce].SasiedniePunkty[2]].Y
						&& X
								== PunktySciezki1[PunktySciezki1[PozycjaNaSciezce].SasiedniePunkty[2]].X) {
					if (OpoznienieDodatniY > SPOWOLNIENIE_KULKI) {
						PoprzednieY = Y;
						Y += 1;
						if (Y
								== PunktySciezki1[PunktySciezki1[PozycjaNaSciezce].SasiedniePunkty[2]].Y) {
							PozycjaNaSciezce =
									PunktySciezki1[PunktySciezki1[PozycjaNaSciezce].SasiedniePunkty[2]].NumerPunktu;

							if (PozycjaNaSciezce == IloscPunktowSciezki1) {
								Wygrana = 1;
							}
						}

						OpoznienieDodatniY = 0;
					}

					OpoznienieDodatniY += 1;

				}

			} else if (WybranyPoziom == 1) {
				if (PunktySciezki2[PozycjaNaSciezce].SasiedniePunkty[2] != 0
						&& Y
								< PunktySciezki2[PunktySciezki2[PozycjaNaSciezce].SasiedniePunkty[2]].Y
						&& X
								== PunktySciezki2[PunktySciezki2[PozycjaNaSciezce].SasiedniePunkty[2]].X) {
					if (OpoznienieDodatniY > SPOWOLNIENIE_KULKI) {
						PoprzednieY = Y;
						Y += 1;
						if (Y
								== PunktySciezki2[PunktySciezki2[PozycjaNaSciezce].SasiedniePunkty[2]].Y) {
							PozycjaNaSciezce =
									PunktySciezki2[PunktySciezki2[PozycjaNaSciezce].SasiedniePunkty[2]].NumerPunktu;

							if (PozycjaNaSciezce == IloscPunktowSciezki2) {
								Wygrana = 1;
							}
						}

						OpoznienieDodatniY = 0;
					}

					OpoznienieDodatniY += 1;
				}

			} else if (WybranyPoziom == 2) {
				if (PunktySciezki3[PozycjaNaSciezce].SasiedniePunkty[2] != 0
						&& Y
								< PunktySciezki3[PunktySciezki3[PozycjaNaSciezce].SasiedniePunkty[2]].Y
						&& X
								== PunktySciezki3[PunktySciezki3[PozycjaNaSciezce].SasiedniePunkty[2]].X) {
					if (OpoznienieDodatniY > SPOWOLNIENIE_KULKI) {
						PoprzednieY = Y;
						Y += 1;
						if (Y
								== PunktySciezki3[PunktySciezki3[PozycjaNaSciezce].SasiedniePunkty[2]].Y) {
							PozycjaNaSciezce =
									PunktySciezki3[PunktySciezki3[PozycjaNaSciezce].SasiedniePunkty[2]].NumerPunktu;

							if (PozycjaNaSciezce == IloscPunktowSciezki3) {
								Wygrana = 1;
							}
						}

						OpoznienieDodatniY = 0;
					}

					OpoznienieDodatniY += 1;
				}
			}

		} else if (X_post < -5000) //bylo -10000
				{
			fMovedX = 1;
			fMovedY = 1;

			/*if (Y > 25)
			 Y -= 1;*/

			if (WybranyPoziom == 0) {
				if (PunktySciezki1[PozycjaNaSciezce].SasiedniePunkty[3] != 0
						&& Y
								> PunktySciezki1[PunktySciezki1[PozycjaNaSciezce].SasiedniePunkty[3]].Y
						&& X
								== PunktySciezki1[PunktySciezki1[PozycjaNaSciezce].SasiedniePunkty[3]].X) {
					if (OpoznienieUjemnyY > SPOWOLNIENIE_KULKI) {
						PoprzednieY = Y;
						Y -= 1;
						if (Y
								== PunktySciezki1[PunktySciezki1[PozycjaNaSciezce].SasiedniePunkty[3]].Y) {
							PozycjaNaSciezce =
									PunktySciezki1[PunktySciezki1[PozycjaNaSciezce].SasiedniePunkty[3]].NumerPunktu;

							if (PozycjaNaSciezce == IloscPunktowSciezki1) {
								Wygrana = 1;
							}
						}

						OpoznienieUjemnyY = 0;
					}

					OpoznienieUjemnyY += 1;
				}

			} else if (WybranyPoziom == 1) {
				if (PunktySciezki2[PozycjaNaSciezce].SasiedniePunkty[3] != 0
						&& Y
								> PunktySciezki2[PunktySciezki2[PozycjaNaSciezce].SasiedniePunkty[3]].Y
						&& X
								== PunktySciezki2[PunktySciezki2[PozycjaNaSciezce].SasiedniePunkty[3]].X) {
					if (OpoznienieUjemnyY > SPOWOLNIENIE_KULKI) {
						PoprzednieY = Y;
						Y -= 1;
						if (Y
								== PunktySciezki2[PunktySciezki2[PozycjaNaSciezce].SasiedniePunkty[3]].Y) {
							PozycjaNaSciezce =
									PunktySciezki2[PunktySciezki2[PozycjaNaSciezce].SasiedniePunkty[3]].NumerPunktu;

							if (PozycjaNaSciezce == IloscPunktowSciezki2) {
								Wygrana = 1;
							}
						}

						OpoznienieUjemnyY = 0;
					}

					OpoznienieUjemnyY += 1;
				}

			} else if (WybranyPoziom == 2) {
				if (PunktySciezki3[PozycjaNaSciezce].SasiedniePunkty[3] != 0
						&& Y
								> PunktySciezki3[PunktySciezki3[PozycjaNaSciezce].SasiedniePunkty[3]].Y
						&& X
								== PunktySciezki3[PunktySciezki3[PozycjaNaSciezce].SasiedniePunkty[3]].X) {
					if (OpoznienieUjemnyY > SPOWOLNIENIE_KULKI) {
						PoprzednieY = Y;
						Y -= 1;
						if (Y
								== PunktySciezki3[PunktySciezki3[PozycjaNaSciezce].SasiedniePunkty[3]].Y) {
							PozycjaNaSciezce =
									PunktySciezki3[PunktySciezki3[PozycjaNaSciezce].SasiedniePunkty[3]].NumerPunktu;

							if (PozycjaNaSciezce == IloscPunktowSciezki3) {
								Wygrana = 1;
							}
						}

						OpoznienieUjemnyY = 0;
					}

					OpoznienieUjemnyY += 1;
				}
			}
		}

		if (fMovedY == 1 && (Y_post <= 2500 && Y_post >= -2500) //bylo 10000
		|| (Y_post > 20000 || Y_post < -20000)) {
			ResetTimeY += 1;

		} else if (fMovedY == 1 && (Y_post > 2500 || Y_post < -2500)) //bylo 10000
				{
			ResetTimeY = 0;
		}

		if (fMovedX == 1 && (X_post <= 2500 && X_post >= -2500) //bylo 10000
		|| (X_post > 20000 || X_post < -20000)) {
			ResetTimeX += 1;

		} else if (fMovedX == 1 && (X_post > 2500 || X_post < -2500)) //bylo 10000
				{
			ResetTimeX = 0;
		}

		if (ResetTimeX >= 500) {
			X_post = 0;

			ResetTimeX = 0;
			fMovedX = 0;
		}

		if (ResetTimeY >= 500) {
			Y_post = 0;

			ResetTimeY = 0;
			fMovedY = 0;
		}

		if (StanGry == Gra && RozpoczetoNowaGre == 0) {
			BSP_LCD_SetTextColor(LCD_COLOR_WHITE);
			BSP_LCD_FillRect(PoprzednieX - 6, PoprzednieY - 6, 13, 13);

			BSP_LCD_SetTextColor(LCD_COLOR_RED);
			BSP_LCD_FillCircle(X, Y, 5);

			BSP_LCD_SetTextColor(LCD_COLOR_WHITE);
		}
	}

	/* USER CODE END Callback 0 */
	if (htim->Instance == TIM6) {
		HAL_IncTick();
	}
}

void Error_Handler(void) {
}

/************************ (C) COPYRIGHT STMicroelectronics *****END OF FILE****/
